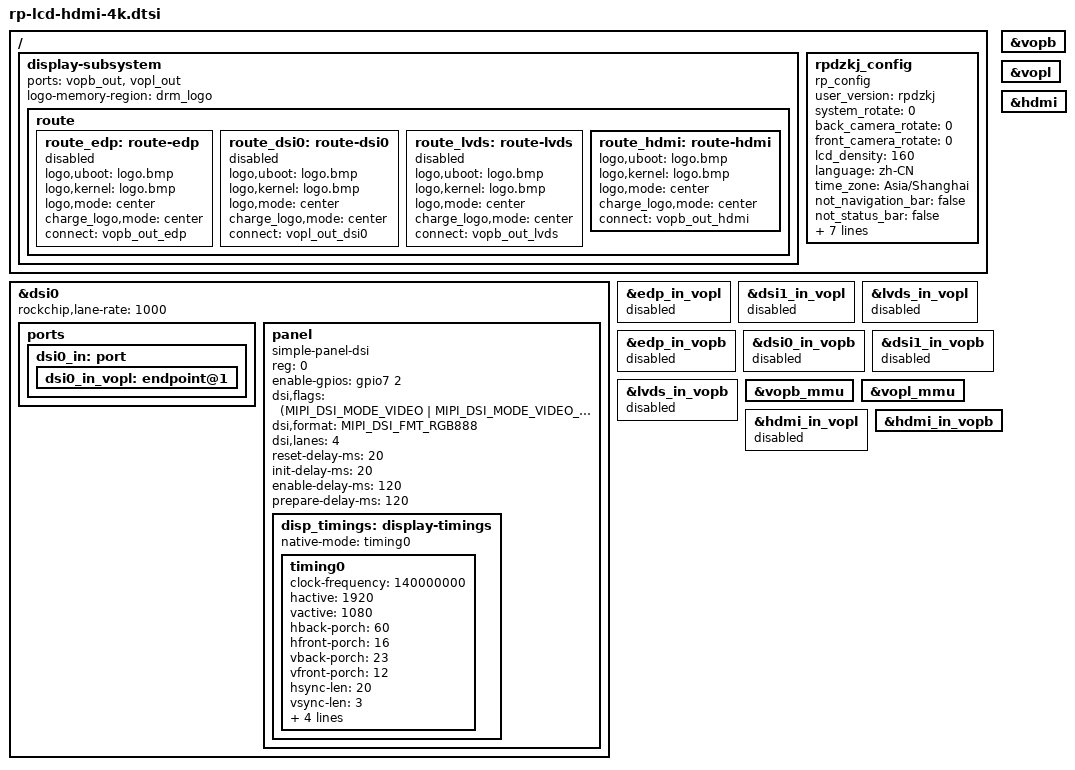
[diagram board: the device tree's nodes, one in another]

/ {

	display-subsystem {
		status = "okay";

		ports = <&vopb_out>, <&vopl_out>;
		logo-memory-region = <&drm_logo>;

		route {
			route_edp: route-edp {
				status = "disabled";
				logo,uboot = "logo.bmp";
				logo,kernel = "logo.bmp";
				logo,mode = "center";
				charge_logo,mode = "center";
				connect = <&vopb_out_edp>;
			};

			route_dsi0: route-dsi0 {
				status = "disabled";
				logo,uboot = "logo.bmp";
				logo,kernel = "logo.bmp";
				logo,mode = "center";
				charge_logo,mode = "center";
				connect = <&vopl_out_dsi0>;
			};

			route_lvds: route-lvds {
				status = "disabled";
				logo,uboot = "logo.bmp";
				logo,kernel = "logo.bmp";
				logo,mode = "center";
				charge_logo,mode = "center";
				connect = <&vopb_out_lvds>;
			};

			route_hdmi: route-hdmi {
				status = "disabled";
				logo,uboot = "logo.bmp";
				logo,kernel = "logo.bmp";
				logo,mode = "center";
				charge_logo,mode = "center";
				connect = <&vopb_out_hdmi>;
			};
		};
	};
	                
	
	
        //bill
        rpdzkj_config {
                compatible = "rp_config";
                user_version = "rpdzkj";
                system_rotate = "0";
                back_camera_rotate = "0";
                front_camera_rotate = "0";
                lcd_density = "160";
                language = "zh-CN";   //zh-CN //en-US
                time_zone = "Asia/Shanghai"; //Asia/Shanghai = +8   //Europe/London  = +1	//Africa/Casablanca	= +0;
                not_navigation_bar = "false";
                not_status_bar = "false";
                default_launcher = "true";
                has_root = "true";
                usb_not_permission = "true";  
                usb_camera_only_front = "false";
                gps_use = "false";
                gps_serial_port = "/dev/ttyS4";
		//		primary_device = "LVDS";
		//		extend_device = "HDMI-A";
		//		extend_rotate = "0";
		rotation_efull = "false";
                status = "okay";
        };
	
};
&dsi0 {
        status = "okay";
        rockchip,lane-rate = <1000>;

	ports {
		dsi0_in: port {
			dsi0_in_vopl: endpoint@1 {
				status = "disabled";
			};
		};
	};
        panel: panel {
                compatible = "simple-panel-dsi";
                reg = <0>;
               // backlight = <&backlight>;
                enable-gpios = <&gpio7 2 GPIO_ACTIVE_HIGH>;
		//power-supply = <&vcc_lcd>;
                dsi,flags = <(MIPI_DSI_MODE_VIDEO | MIPI_DSI_MODE_VIDEO_BURST)>;
                dsi,format = <MIPI_DSI_FMT_RGB888>;
                dsi,lanes = <4>;
                reset-delay-ms = <20>;
                init-delay-ms = <20>;
                enable-delay-ms = <120>;
                prepare-delay-ms = <120>;
                status = "okay";

                disp_timings: display-timings {
                        native-mode = <&timing0>;

                        timing0: timing0 {
                                clock-frequency = <140000000>;
                                hactive = <1920>;
                                vactive = <1080>;
                                hback-porch = <60>;
                                hfront-porch = <16>;
                                vback-porch = <23>;
                                vfront-porch = <12>;
                                hsync-len = <20>;
                                vsync-len = <3>;
                                hsync-active = <0>;
                                vsync-active = <0>;
                                de-active = <0>;
                                pixelclk-active = <0>;
                        };
                };
        };
};

&route_hdmi {
        status = "okay";
};

&edp_in_vopl {
        status = "disabled";
};
&dsi0_in_vopl {
        status = "okay";
};
&dsi1_in_vopl {
        status = "disabled";
};
&lvds_in_vopl {
        status = "disabled";
};

&edp_in_vopb {
        status = "disabled";
};
&dsi0_in_vopb {
        status = "disabled";
};
&dsi1_in_vopb {
        status = "disabled";
};
&lvds_in_vopb {
        status = "disabled";
};

&vopb {
	status = "okay";
};

&vopb_mmu {
	status = "okay";
};

&vopl {
	status = "okay";
};

&vopl_mmu {
	status = "okay";
};

&hdmi {
	#address-cells = <1>;
	#size-cells = <0>;
	#sound-dai-cells = <0>;
	status = "okay";
};

&hdmi_in_vopl {
        status = "disabled";
};
&hdmi_in_vopb {
        status = "okay";
};
